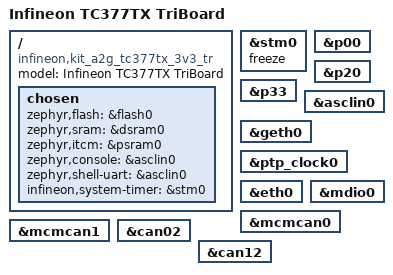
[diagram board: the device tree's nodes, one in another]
/*
 * Copyright (c) 2024 Infineon Technologies AG
 *
 * SPDX-License-Identifier: Apache-2.0
 */

/dts-v1/;

#include <infineon/tc3x/tc377tx.dtsi>
#include "kit_a2g_tc377tx_3v3_tr.dtsi"

/ {
	model = "Infineon TC377TX TriBoard";
	compatible = "infineon,kit_a2g_tc377tx_3v3_tr",
	             "infineon,tc377tx",
	             "infineon,tc3x";

	chosen {
		zephyr,flash = &flash0;
		zephyr,sram = &dsram0;
		zephyr,itcm = &psram0;
		zephyr,console = &asclin0;
		zephyr,shell-uart = &asclin0;
		infineon,system-timer = &stm0;
	};
};

&stm0 {
	status = "okay";
	freeze;
};

&p00 {
	status = "okay";
};

&p20 {
	status = "okay";
};

&p33 {
	status = "okay";
};

&asclin0 {
	status = "okay";
};

&geth0 {
	status = "okay";
};

&ptp_clock0 {
	status = "okay";
};

&eth0 {
	status = "okay";
};

&mdio0 {
	status = "okay";
};

&mcmcan0 {
	status = "okay";
};
&mcmcan1 {
	status = "okay";
};

&can02 {
	status = "okay";
};
&can12 {
	status = "okay";
};
